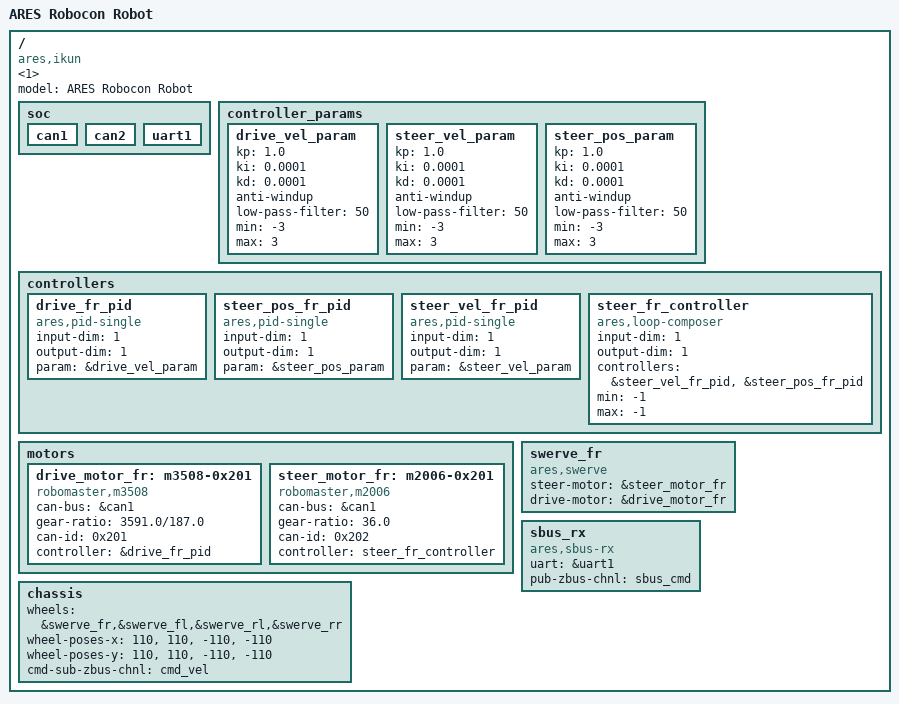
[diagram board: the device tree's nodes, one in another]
/{
    #address-cells <1>;
    #size-cells <1>;
    model = "ARES Robocon Robot";
    compatible = "ares,ikun";

    soc {
        can1: can1 {
            status = "okay";
        };
        can2: can2 {
            status = "okay";
        };
        uart1: uart1{
            status = "okay";
        };
    };

    controller_params{
        drive_vel_param: drive_vel_param{
            kp = "1.0"; // dts does not support floating point, use string instead!
            ki = "0.0001";
            kd = "0.0001";
            anti-windup;
            low-pass-filter = "50"; // Hz
            min = "-3"; // Nm
            max = "3";
        };
        steer_vel_param: steer_vel_param{
            kp = "1.0"; // dts does not support floating point, use string instead!
            ki = "0.0001";
            kd = "0.0001";
            anti-windup;
            low-pass-filter = "50"; // Hz
            min = "-3"; // Nm
            max = "3";
        };
        steer_pos_param: steer_pos_param{
            kp = "1.0"; // dts does not support floating point, use string instead!
            ki = "0.0001";
            kd = "0.0001";
            anti-windup;
            low-pass-filter = "50"; // Hz
            min = "-3"; // Nm
            max = "3";
        };
    };

    controllers {
        drive_fr_pid: drive_fr_pid{
            compatible = "ares,pid-single";
            input-dim = <1>;
            output-dim = <1>;
            param = &drive_vel_param;
        };
        steer_pos_fr_pid: steer_pos_fr_pid{
            compatible = "ares,pid-single";
            input-dim = <1>;
            output-dim = <1>;
            param = &steer_pos_param;
        };
        steer_vel_fr_pid: steer_vel_fr_pid{
            compatible = "ares,pid-single";
            input-dim = <1>;
            output-dim = <1>;
            param = &steer_vel_param;
        };
        steer_fr_controller: steer_fr_controller{
            compatible = "ares,loop-composer";
            input-dim = <1>; // 1 only angel ref, 2 angle ref and speed ff, 3 angle ref speed ff and torque ff.
            output-dim = <1>;
            controllers = &steer_vel_fr_pid, &steer_pos_fr_pid;
            min = "-1";
            max= "-1";
        };
    };

    motors {
        drive_motor_fr: m3508-0x201 {
            compatible = "robomaster,m3508";
            can-bus = &can1;
            gear-ratio = "3591.0/187.0"; //dts does not support floating point, use string instead!
            can-id = <0x201>;
            controller = &drive_fr_pid;
            status = "okay";
        };
        steer_motor_fr: m2006-0x201 {
            compatible = "robomaster,m2006";
            can-bus = &can1;
            gear-ratio = "36.0"; // dts does not support floating point, use string instead!
            can-id = <0x202>;
            controller = <&steer_fr_controller>;
            status = "okay";
        };
        // define all the motors needed ...
    };

    swerve_fr: swerve_fr{
        compatible = "ares,swerve";
        steer-motor= &steer_motor_fr;
        drive-motor= &drive_motor_fr;
    };

    sbus_rx: sbus_rx{
        compatible = "ares,sbus-rx";
        uart = &uart1;
        pub-zbus-chnl = "sbus_cmd";
    };

    // define all mechanism/high level device nedded ...

    chassis:chassis{
        wheels = &swerve_fr,&swerve_fl,&swerve_rl,&swerve_rr;
        wheel-poses-x = "110","110","-110","-110"; // x pos of each wheel in mm
        wheel-poses-y = "110","110","-110","-110"; // y pos of each wheel in mm
        cmd-sub-zbus-chnl = "cmd_vel";
    };
};
